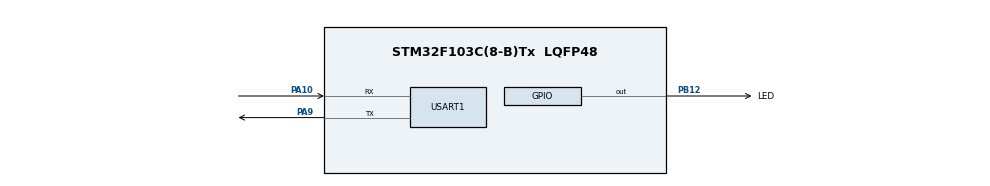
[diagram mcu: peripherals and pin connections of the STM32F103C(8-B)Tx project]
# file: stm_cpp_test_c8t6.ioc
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Mcu.Family=STM32F1
Mcu.Name=STM32F103C(8-B)Tx
Mcu.Package=LQFP48
NVIC.PriorityGroup=NVIC_PRIORITYGROUP_4
NVIC.USART1_IRQn=true\:0\:0\:false\:false\:true\:true\:true
PA10.Mode=Asynchronous
PA10.Signal=USART1_RX
PA13.Mode=Serial_Wire
PA13.Signal=SYS_JTMS-SWDIO
PA14.Mode=Serial_Wire
PA14.Signal=SYS_JTCK-SWCLK
PA9.Mode=Asynchronous
PA9.Signal=USART1_TX
PB12.GPIO_Label=LED
PB12.Signal=GPIO_Output
ProjectManager.HeapSize=0x200
ProjectManager.StackSize=0x400
ProjectManager.TargetToolchain=STM32CubeIDE
RCC.APB1Freq_Value=8000000
RCC.APB2Freq_Value=8000000
USART1.VirtualMode=VM_ASYNC
board=custom

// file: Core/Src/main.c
/* USER CODE BEGIN Header */
/**
  ******************************************************************************
  * @file           : main.c
  * @brief          : Main program body
  ******************************************************************************
  * @attention
  *
  * <h2><center>&copy; Copyright (c) 2020 STMicroelectronics.
  * All rights reserved.</center></h2>
  *
  * This software component is licensed by ST under BSD 3-Clause license,
  * the "License"; You may not use this file except in compliance with the
  * License. You may obtain a copy of the License at:
  *                        opensource.org/licenses/BSD-3-Clause
  *
  ******************************************************************************
  */
/* USER CODE END Header */

#include "main.h"

/* USER CODE BEGIN Includes */
#include <stdio.h>
/* USER CODE END Includes */

UART_HandleTypeDef huart1;

void SystemClock_Config(void);
static void MX_GPIO_Init(void);
static void MX_USART1_UART_Init(void);

/* USER CODE BEGIN 0 */

void blink_led_fast() {
	for (int i = 1; i <= 10; i++) {
		HAL_GPIO_TogglePin(LED_GPIO_Port, LED_Pin);
		HAL_Delay(50);
	}
	HAL_GPIO_WritePin(LED_GPIO_Port, LED_Pin, GPIO_PIN_SET);
}
void blink_led_slow() {
	HAL_GPIO_WritePin(LED_GPIO_Port, LED_Pin, GPIO_PIN_RESET);
	HAL_Delay(500);
	HAL_GPIO_WritePin(LED_GPIO_Port, LED_Pin, GPIO_PIN_SET);
	HAL_Delay(500);
}

int blink_flag = 0;
void USART_Rx_Callback(UART_HandleTypeDef *huart, UART_RxBuffer *rxbuff) {
	if (huart == (&huart1)) {
		// Deal With Rx 1
		nm_addname((char *)rxbuff->uRx_Data);
		uart_fputs(&huart1, "Name Added: ");
		uart_fputs(&huart1, (char *)rxbuff->uRx_Data);
		uart_fputs(&huart1, "\r\n");
		int max_cnt = nm_highestrepeat();
		/* ATTENTION: DO NOT USE HAL_DELAY IN USART INTERRUPT CALLBACK !!!!!!!!!!!! */
		// HAL_Delay(100);
		char out_tmp[35];
		sprintf(out_tmp, "Highest Repeat Times : %d\n", max_cnt);
		uart_fputs(&huart1, out_tmp);
		// blink_led_fast();
		blink_flag = 1;
	}
	else {
		// Not Rx
	}
}

/* USER CODE END 0 */

int main(void)
{

  /* MCU Configuration--------------------------------------------------------*/

  /* Reset of all peripherals, Initializes the Flash interface and the Systick. */
  HAL_Init();

  /* Configure the system clock */
  SystemClock_Config();

  /* Initialize all configured peripherals */
  MX_GPIO_Init();
  MX_USART1_UART_Init();
  /* USER CODE BEGIN 2 */
  uart_fputs(&huart1, "-------------\r\nSystem Setup\r\n");
  HAL_GPIO_WritePin(LED_GPIO_Port, LED_Pin, GPIO_PIN_SET);
  init_USART_RxBuffer(&USART1_Buffer);
  /* USER CODE END 2 */

  /* Infinite loop */
  while (1)
  {

    /* USER CODE BEGIN 3 */
	  if (blink_flag == 1){
		  blink_led_fast();
		  blink_flag = 0;
	  }
	  else
		  blink_led_slow();
  }
  /* USER CODE END 3 */
}

void SystemClock_Config(void)
{
  RCC_OscInitTypeDef RCC_OscInitStruct = {0};
  RCC_ClkInitTypeDef RCC_ClkInitStruct = {0};

  /** Initializes the CPU, AHB and APB busses clocks
  */
  RCC_OscInitStruct.OscillatorType = RCC_OSCILLATORTYPE_HSI;
  RCC_OscInitStruct.HSIState = RCC_HSI_ON;
  RCC_OscInitStruct.HSICalibrationValue = RCC_HSICALIBRATION_DEFAULT;
  RCC_OscInitStruct.PLL.PLLState = RCC_PLL_NONE;
  if (HAL_RCC_OscConfig(&RCC_OscInitStruct) != HAL_OK)
  {
    Error_Handler();
  }
  /** Initializes the CPU, AHB and APB busses clocks
  */
  RCC_ClkInitStruct.ClockType = RCC_CLOCKTYPE_HCLK|RCC_CLOCKTYPE_SYSCLK
                              |RCC_CLOCKTYPE_PCLK1|RCC_CLOCKTYPE_PCLK2;
  RCC_ClkInitStruct.SYSCLKSource = RCC_SYSCLKSOURCE_HSI;
  RCC_ClkInitStruct.AHBCLKDivider = RCC_SYSCLK_DIV1;
  RCC_ClkInitStruct.APB1CLKDivider = RCC_HCLK_DIV1;
  RCC_ClkInitStruct.APB2CLKDivider = RCC_HCLK_DIV1;

  if (HAL_RCC_ClockConfig(&RCC_ClkInitStruct, FLASH_LATENCY_0) != HAL_OK)
  {
    Error_Handler();
  }
}

static void MX_USART1_UART_Init(void)
{

  huart1.Instance = USART1;
  huart1.Init.BaudRate = 115200;
  huart1.Init.WordLength = UART_WORDLENGTH_8B;
  huart1.Init.StopBits = UART_STOPBITS_1;
  huart1.Init.Parity = UART_PARITY_NONE;
  huart1.Init.Mode = UART_MODE_TX_RX;
  huart1.Init.HwFlowCtl = UART_HWCONTROL_NONE;
  huart1.Init.OverSampling = UART_OVERSAMPLING_16;
  if (HAL_UART_Init(&huart1) != HAL_OK)
  {
    Error_Handler();
  }

}

static void MX_GPIO_Init(void)
{
  GPIO_InitTypeDef GPIO_InitStruct = {0};

  /* GPIO Ports Clock Enable */
  __HAL_RCC_GPIOB_CLK_ENABLE();
  __HAL_RCC_GPIOA_CLK_ENABLE();

  /*Configure GPIO pin Output Level */
  HAL_GPIO_WritePin(LED_GPIO_Port, LED_Pin, GPIO_PIN_RESET);

  /*Configure GPIO pin : LED_Pin */
  GPIO_InitStruct.Pin = LED_Pin;
  GPIO_InitStruct.Mode = GPIO_MODE_OUTPUT_PP;
  GPIO_InitStruct.Pull = GPIO_NOPULL;
  GPIO_InitStruct.Speed = GPIO_SPEED_FREQ_LOW;
  HAL_GPIO_Init(LED_GPIO_Port, &GPIO_InitStruct);

}

void Error_Handler(void)
{
}

/************************ (C) COPYRIGHT STMicroelectronics *****END OF FILE****/
